# MDR1986BE4 register map
Registers from a debugger description file.
Registers are 32-bit, access not given, no defined reset value unless marked. A register's access mark holds for its fields unless they carry their own. Addresses are absolute; registers are grouped by the start of their names; lines under a group give offsets from that group; [hi:lo] are bit positions; {n}, {i} and the like mark numbered series; 'fields as' and 'values as' point back to an identical list; <NAME> marks a mode.

## EEPROM
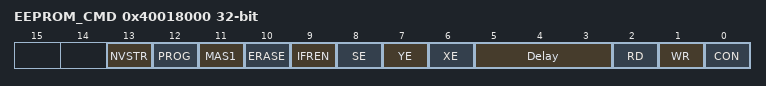
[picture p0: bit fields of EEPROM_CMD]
0x40018000 EEPROM_CMD
  [13] NVSTR, [12] PROG, [11] MAS1, [10] ERASE, [9] IFREN, [8] SE, [7] YE, [6] XE, [5:3] Delay, [2] RD, [1] WR, [0] CON
0x40018004 EEPROM_ADR
0x40018008 EEPROM_DI
  [31:0] DATA
0x4001800C EEPROM_DO
  [31:0] DATA
0x40018010 EEPROM_KEY

## RST
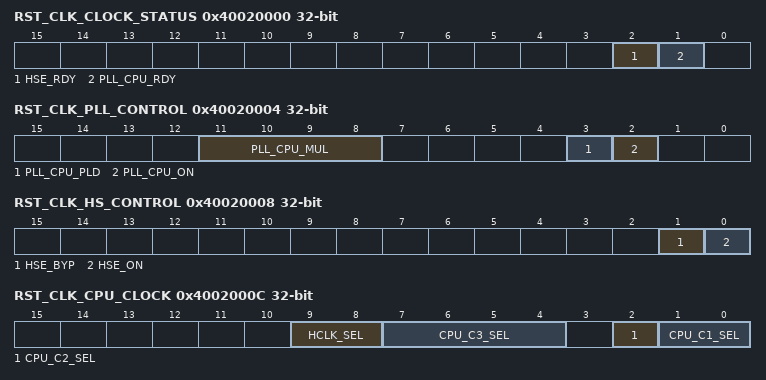
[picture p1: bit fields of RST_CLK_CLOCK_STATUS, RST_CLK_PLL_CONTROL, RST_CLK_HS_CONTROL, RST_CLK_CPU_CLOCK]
0x40020000 RST_CLK_CLOCK_STATUS
  [2] HSE_RDY, [1] PLL_CPU_RDY
0x40020004 RST_CLK_PLL_CONTROL
  [11:8] PLL_CPU_MUL, [3] PLL_CPU_PLD, [2] PLL_CPU_ON
0x40020008 RST_CLK_HS_CONTROL
  [1] HSE_BYP, [0] HSE_ON
0x4002000C RST_CLK_CPU_CLOCK
  [9:8] HCLK_SEL, [7:4] CPU_C3_SEL, [2] CPU_C2_SEL, [1:0] CPU_C1_SEL
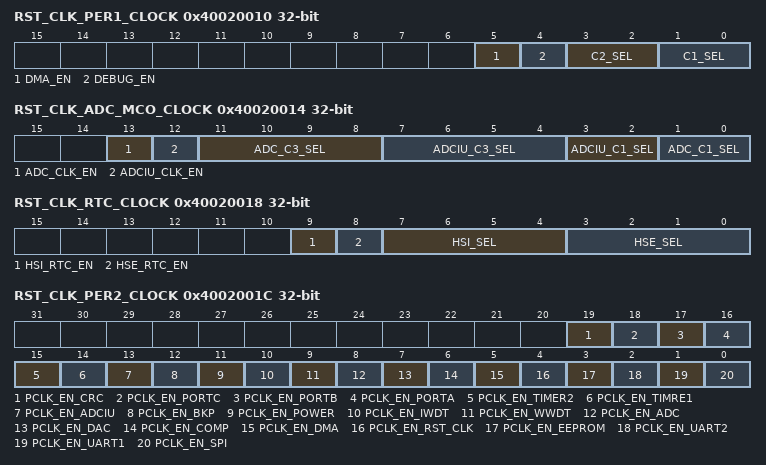
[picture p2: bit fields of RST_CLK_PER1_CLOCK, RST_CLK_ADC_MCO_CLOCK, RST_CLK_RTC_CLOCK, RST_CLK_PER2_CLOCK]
0x40020010 RST_CLK_PER1_CLOCK
  [5] DMA_EN, [4] DEBUG_EN, [3:2] C2_SEL, [1:0] C1_SEL
0x40020014 RST_CLK_ADC_MCO_CLOCK
  [13] ADC_CLK_EN, [12] ADCIU_CLK_EN, [11:8] ADC_C3_SEL, [7:4] ADCIU_C3_SEL, [3:2] ADCIU_C1_SEL, [1:0] ADC_C1_SEL
0x40020018 RST_CLK_RTC_CLOCK
  [9] HSI_RTC_EN, [8] HSE_RTC_EN, [7:4] HSI_SEL, [3:0] HSE_SEL
0x4002001C RST_CLK_PER2_CLOCK
  [19] PCLK_EN_CRC, [18] PCLK_EN_PORTC, [17] PCLK_EN_PORTB, [16] PCLK_EN_PORTA, [15] PCLK_EN_TIMER2, [14] PCLK_EN_TIMRE1, [13] PCLK_EN_ADCIU, [12] PCLK_EN_BKP, [11] PCLK_EN_POWER, [10] PCLK_EN_IWDT, [9] PCLK_EN_WWDT, [8] PCLK_EN_ADC, [7] PCLK_EN_DAC, [6] PCLK_EN_COMP, [5] PCLK_EN_DMA, [4] PCLK_EN_RST_CLK, [3] PCLK_EN_EEPROM, [2] PCLK_EN_UART2, [1] PCLK_EN_UART1, [0] PCLK_EN_SPI
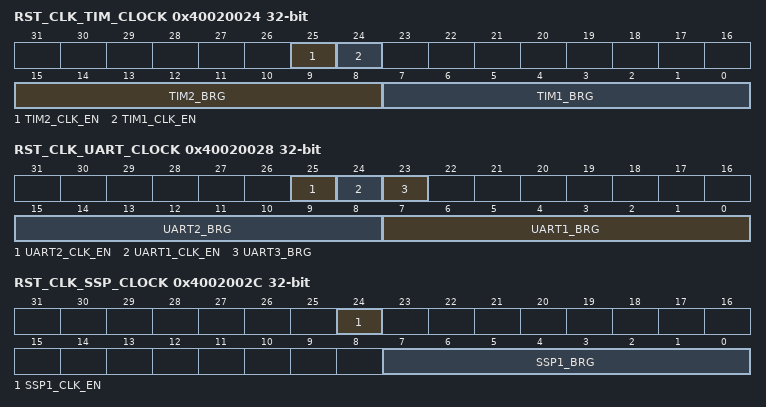
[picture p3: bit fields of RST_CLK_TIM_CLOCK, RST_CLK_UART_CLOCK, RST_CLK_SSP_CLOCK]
0x40020024 RST_CLK_TIM_CLOCK
  [25] TIM2_CLK_EN, [24] TIM1_CLK_EN, [15:8] TIM2_BRG, [7:0] TIM1_BRG
0x40020028 RST_CLK_UART_CLOCK
  [25] UART2_CLK_EN, [24] UART1_CLK_EN, [23] UART3_BRG, [15:8] UART2_BRG, [7:0] UART1_BRG
0x4002002C RST_CLK_SSP_CLOCK
  [24] SSP1_CLK_EN, [7:0] SSP1_BRG

## DMA
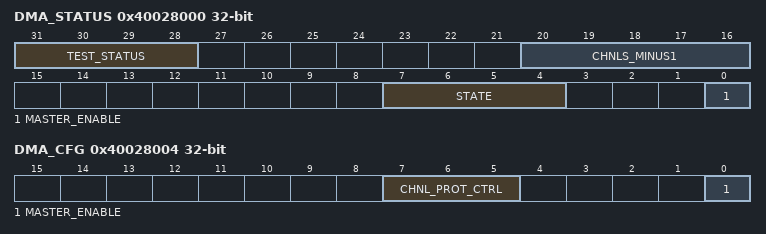
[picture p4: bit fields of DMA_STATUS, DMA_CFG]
0x40028000 DMA_STATUS
  [31:28] TEST_STATUS, [20:16] CHNLS_MINUS1, [7:4] STATE, [0] MASTER_ENABLE
0x40028004 DMA_CFG
  [7:5] CHNL_PROT_CTRL, [0] MASTER_ENABLE
0x40028008 DMA_CTRL_BASE_PTR
0x4002800C DMA_ALT_CTRL_BASE_PTR
0x40028010 DMA_WAITONREQ_STATUS
0x40028014 DMA_CHNL_SW_REQUEST
0x40028018 DMA_CHNL_USEBURST_SET
0x4002801C DMA_CHNL_USEBURST_CLR
0x40028020 DMA_CHNL_REQ_MASK_SET
0x40028024 DMA_CHNL_REQ_MASK_CLR
0x40028028 DMA_CHNL_ENABLE_SET
0x4002802C DMA_CHNL_ENABLE_CLR
0x40028030 DMA_CHNL_PRI_ALT_SET
0x40028034 DMA_CHNL_PRI_ALT_CLR
0x40028038 DMA_CHNL_PRIORITY_SET
0x4002803C DMA_CHNL_PRIORITY_CLR
0x4002804C DMA_ERR_CLR
  [0] ERR_CLR

## COMP
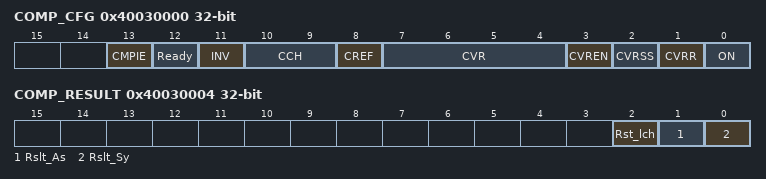
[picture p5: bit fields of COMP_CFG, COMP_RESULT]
0x40030000 COMP_CFG
  [13] CMPIE, [12] Ready, [11] INV, [10:9] CCH, [8] CREF, [7:4] CVR, [3] CVREN, [2] CVRSS, [1] CVRR, [0] ON
0x40030004 COMP_RESULT
  [2] Rst_lch, [1] Rslt_As, [0] Rslt_Sy
0x40030008 COMP_RESULT_LATCH
  [0] Rst_lch

## DAC
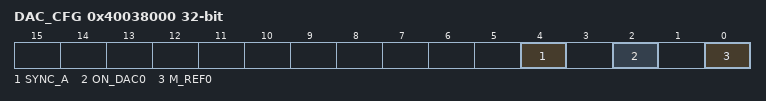
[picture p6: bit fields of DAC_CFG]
0x40038000 DAC_CFG
  [4] SYNC_A, [2] ON_DAC0, [0] M_REF0
0x40038004 DAC_1_DATA
  [11:0] DAC0DATA

## ADC1
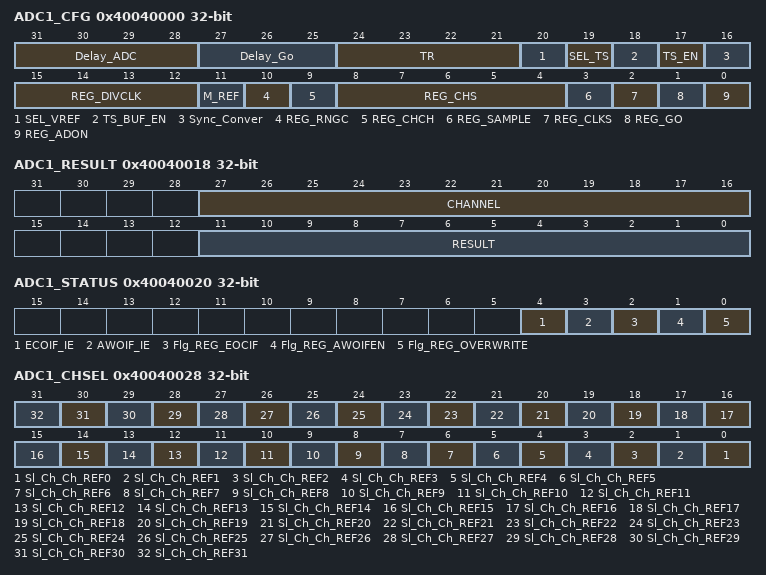
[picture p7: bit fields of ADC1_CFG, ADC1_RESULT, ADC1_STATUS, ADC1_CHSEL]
0x40040000 ADC1_CFG
  [31:28] Delay_ADC, [27:25] Delay_Go, [24:21] TR, [20] SEL_VREF, [19] SEL_TS, [18] TS_BUF_EN, [17] TS_EN, [16] Sync_Conver, [15:12] REG_DIVCLK, [11] M_REF, [10] REG_RNGC, [9] REG_CHCH, [8:4] REG_CHS, [3] REG_SAMPLE, [2] REG_CLKS, [1] REG_GO, [0] REG_ADON
0x40040008 ADC1_H_LEVEL
  [11:0] REG_H_LEVEL
0x40040010 ADC1_L_LEVEL
  [11:0] REG_L_LEVEL
0x40040018 ADC1_RESULT
  [27:16] CHANNEL, [11:0] RESULT
0x40040020 ADC1_STATUS
  [4] ECOIF_IE, [3] AWOIF_IE, [2] Flg_REG_EOCIF, [1] Flg_REG_AWOIFEN, [0] Flg_REG_OVERWRITE
0x40040028 ADC1_CHSEL
  [n] Sl_Ch_Ch_REF{n} (n=0..31)
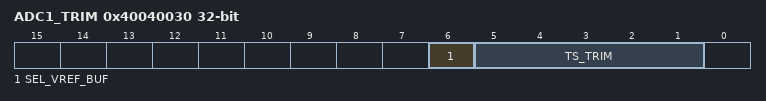
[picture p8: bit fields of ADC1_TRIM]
0x40040030 ADC1_TRIM
  [6] SEL_VREF_BUF, [5:1] TS_TRIM
